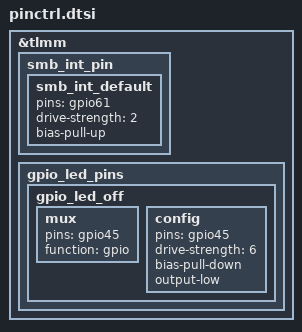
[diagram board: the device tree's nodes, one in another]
/*
 * Copyright (c) 2015-2017, The Linux Foundation. All rights reserved.
 * Copyright (C) 2018 XiaoMi, Inc.
 *
 * This program is free software; you can redistribute it and/or modify
 * it under the terms of the GNU General Public License version 2 and
 * only version 2 as published by the Free Software Foundation.
 *
 * This program is distributed in the hope that it will be useful,
 * but WITHOUT ANY WARRANTY; without even the implied warranty of
 * MERCHANTABILITY or FITNESS FOR A PARTICULAR PURPOSE.  See the
 * GNU General Public License for more details.
 */
&tlmm {
		smb_int_pin {
			smb_int_default: smb_int_default {
				pins = "gpio61";
				drive-strength = <2>;	/*8 MA */
				bias-pull-up;		/* PULL UP*/
			};
		};

		gpio_led_pins {
			gpio_led_off: gpio_led_off {
				mux {
					pins = "gpio45";
					function = "gpio";
				};
				config {
					pins = "gpio45";
					drive-strength = <6>;
					bias-pull-down;
					output-low;
				};
			};
		};
};
